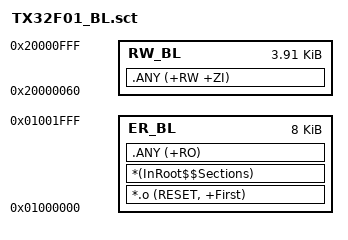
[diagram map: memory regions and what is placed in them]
; ============================================================
;  Bootloader scatter file
;    BL Flash : 0x01000000 - 0x01001FFF   (8 KB)
;    SRAM     : 0x20000060 - 0x20000FFF   (前 96B 留给软向量表)
; ============================================================

LR_BL 0x01000000 0x00002000  {
  ER_BL 0x01000000 0x00002000  {
    *.o (RESET, +First)
    *(InRoot$$Sections)
    .ANY (+RO)
  }
  RW_BL 0x20000060 0x00000FA0  {   ; 0x1000 - 0x60 = 0xFA0
    .ANY (+RW +ZI)
  }
}
